VERSION ""

NS_ :

BS_:

BU_:
	NEO
	MCU
	GTW
	EPAS
	DI
	ESP
	SBW
	STW
	APP
	DAS
	XXX

VAL_TABLE_ StW_AnglHP_Spd 16383 "SNA" ;
VAL_TABLE_ DI_aebFaultReason 15 "DI_AEB_FAULT_DAS_REQ_DI_UNAVAIL" 14 "DI_AEB_FAULT_ACCEL_REQ_INVALID" 13 "DI_AEB_FAULT_MIN_TIME_BTWN_EVENTS" 12 "DI_AEB_FAULT_ESP_MIA" 11 "DI_AEB_FAULT_ESP_FAULT" 10 "DI_AEB_FAULT_EPB_NOT_PARKED" 9 "DI_AEB_FAULT_ACCEL_OUT_OF_BOUNDS" 8 "DI_AEB_FAULT_PM_REQUEST" 7 "DI_AEB_FAULT_VEL_EST_ABNORMAL" 6 "DI_AEB_FAULT_DAS_SNA" 5 "DI_AEB_FAULT_DAS_CONTROL_MIA" 4 "DI_AEB_FAULT_SPEED_DELTA" 3 "DI_AEB_FAULT_EBR_FAULT" 2 "DI_AEB_FAULT_PM_MIA" 1 "DI_AEB_FAULT_EPB_MIA" 0 "DI_AEB_FAULT_NONE" ;
VAL_TABLE_ DI_aebLockState 3 "AEB_LOCK_STATE_SNA" 2 "AEB_LOCK_STATE_UNUSED" 1 "AEB_LOCK_STATE_UNLOCKED" 0 "AEB_LOCK_STATE_LOCKED" ;
VAL_TABLE_ DI_aebSmState 7 "DI_AEB_STATE_FAULT" 6 "DI_AEB_STATE_EXIT" 5 "DI_AEB_STATE_STANDSTILL" 4 "DI_AEB_STATE_STOPPING" 3 "DI_AEB_STATE_ENABLE" 2 "DI_AEB_STATE_ENABLE_INIT" 1 "DI_AEB_STATE_STANDBY" 0 "DI_AEB_STATE_UNAVAILABLE" ;
VAL_TABLE_ DI_aebState 7 "AEB_CAN_STATE_SNA" 4 "AEB_CAN_STATE_FAULT" 3 "AEB_CAN_STATE_STANDSTILL" 2 "AEB_CAN_STATE_ENABLED" 1 "AEB_CAN_STATE_STANDBY" 0 "AEB_CAN_STATE_UNAVAILABLE" ;
VAL_TABLE_ DI_epbInterfaceReady 1 "EPB_INTERFACE_READY" 0 "EPB_INTERFACE_NOT_READY" ;
VAL_TABLE_ DI_gear 7 "DI_GEAR_SNA" 4 "DI_GEAR_D" 3 "DI_GEAR_N" 2 "DI_GEAR_R" 1 "DI_GEAR_P" 0 "DI_GEAR_INVALID" ;
VAL_TABLE_ DI_gpoReason 8 "DI_GPO_NUMREASONS" 7 "DI_GPO_CAPACITOR_OVERTEMP" 6 "DI_GPO_NOT_ENOUGH_12V" 5 "DI_GPO_NO_BATTERY_POWER" 4 "DI_GPO_AMBIENT_OVERTEMP" 3 "DI_GPO_FLUID_DELTAT" 2 "DI_GPO_STATOR_OVERTEMP" 1 "DI_GPO_HEATSINK_OVERTEMP" 0 "DI_GPO_OUTLET_OVERTEMP" ;
VAL_TABLE_ DI_immobilizerCondition 1 "DI_IMM_CONDITION_LEARNED" 0 "DI_IMM_CONDITION_VIRGIN_SNA" ;
VAL_TABLE_ DI_immobilizerState 7 "DI_IMM_STATE_FAULT" 6 "DI_IMM_STATE_FAULTRETRY" 5 "DI_IMM_STATE_RESET" 4 "DI_IMM_STATE_LEARN" 3 "DI_IMM_STATE_DISARMED" 2 "DI_IMM_STATE_AUTHENTICATING" 1 "DI_IMM_STATE_REQUEST" 0 "DI_IMM_STATE_INIT_SNA" ;
VAL_TABLE_ DI_limpReason 24 "DI_LIMP_NUMREASONS" 23 "DI_LIMP_CAPACITOR_OVERTEMP" 22 "DI_LIMP_GTW_MIA" 21 "DI_LIMP_TRQCMD_VALIDITY_UNKNOWN" 20 "DI_LIMP_DI_MIA" 19 "DI_LIMP_CONFIG_MISMATCH" 18 "DI_LIMP_HEATSINK_TEMP" 17 "DI_LIMP_PMREQUEST" 16 "DI_LIMP_PMHEARTBEAT" 15 "DI_LIMP_TRQ_CROSS_CHECK" 14 "DI_LIMP_EXTERNAL_COMMAND" 13 "DI_LIMP_WRONG_CS_CALIBRATION" 12 "DI_LIMP_STATOR_TEMP" 11 "DI_LIMP_DELTAT_TOO_NEGATIVE" 10 "DI_LIMP_DELTAT_TOO_POSITIVE" 9 "DI_LIMP_AMBIENT_TEMP" 8 "DI_LIMP_OUTLET_TEMP" 7 "DI_LIMP_LOW_FLOW" 6 "DI_LIMP_BMS_MIA" 5 "DI_LIMP_12V_SUPPLY_UNDERVOLTAGE" 4 "DI_LIMP_NO_FLUID" 3 "DI_LIMP_NO_FUNC_HEATSINK_SENSOR" 2 "DI_LIMP_NO_FUNC_STATORT_SENSOR" 1 "DI_LIMP_BUSV_SENSOR_IRRATIONAL" 0 "DI_LIMP_PHASE_IMBALANCE" ;
VAL_TABLE_ DI_mode 2 "DI_MODE_DYNO" 1 "DI_MODE_DRIVE" 0 "DI_MODE_UNDEF" ;
VAL_TABLE_ DI_motorType 14 "DI_MOTOR_F2AE" 13 "DI_MOTOR_F2AD" 12 "DI_MOTOR_F2AC" 11 "DI_MOTOR_F2AB" 10 "DI_MOTOR_F1AC" 9 "DI_MOTOR_SSR1A" 8 "DI_MOTOR_F1A" 7 "DI_MOTOR_M7M6" 6 "DI_MOTOR_M8A" 5 "DI_MOTOR_M7M5" 4 "DI_MOTOR_M7M4" 3 "DI_MOTOR_M7M3" 2 "DI_MOTOR_ROADSTER_SPORT" 1 "DI_MOTOR_ROADSTER_BASE" 0 "DI_MOTOR_SNA" ;
VAL_TABLE_ DI_speedUnits 1 "DI_SPEED_KPH" 0 "DI_SPEED_MPH" ;
VAL_TABLE_ DI_state 4 "DI_STATE_ENABLE" 3 "DI_STATE_FAULT" 2 "DI_STATE_CLEAR_FAULT" 1 "DI_STATE_STANDBY" 0 "DI_STATE_PREAUTH" ;
VAL_TABLE_ DI_velocityEstimatorState 4 "VE_STATE_BACKUP_MOTOR" 3 "VE_STATE_BACKUP_WHEELS_B" 2 "VE_STATE_BACKUP_WHEELS_A" 1 "VE_STATE_WHEELS_NORMAL" 0 "VE_STATE_NOT_INITIALIZED" ;

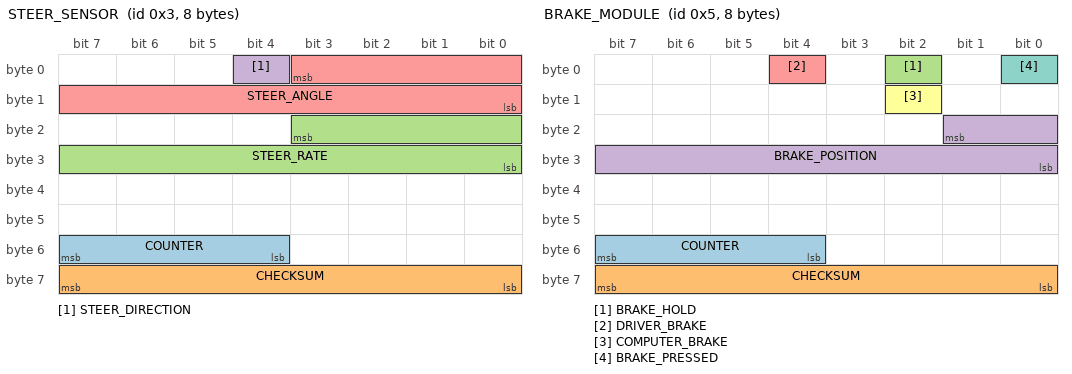
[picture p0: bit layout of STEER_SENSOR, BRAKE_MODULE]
BO_ 3 STEER_SENSOR: 8 XXX
 SG_ COUNTER : 55|4@0+ (1,0) [0|15] "" XXX
 SG_ CHECKSUM : 63|8@0+ (1,0) [0|255] "" XXX
 SG_ STEER_RATE : 19|12@0- (0.5,0) [0|255] "" XXX
 SG_ STEER_DIRECTION : 4|1@0+ (1,2) [0|1] "" XXX
 SG_ STEER_ANGLE : 3|12@0- (-0.5,0) [-500|500] "degrees" XXX

BO_ 5 BRAKE_MODULE: 8 XXX
 SG_ COUNTER : 55|4@0+ (1,0) [0|15] "" XXX
 SG_ CHECKSUM : 63|8@0+ (1,0) [0|255] "" XXX
 SG_ BRAKE_HOLD : 2|1@0+ (1,0) [0|1] "" XXX
 SG_ BRAKE_POSITION : 17|10@0+ (1,0) [0|65535] "" XXX
 SG_ DRIVER_BRAKE : 4|1@0+ (1,0) [0|1] "" XXX
 SG_ COMPUTER_BRAKE : 10|1@0+ (1,0) [0|1] "" XXX
 SG_ BRAKE_PRESSED : 0|1@1+ (1,0) [0|1] "" XXX

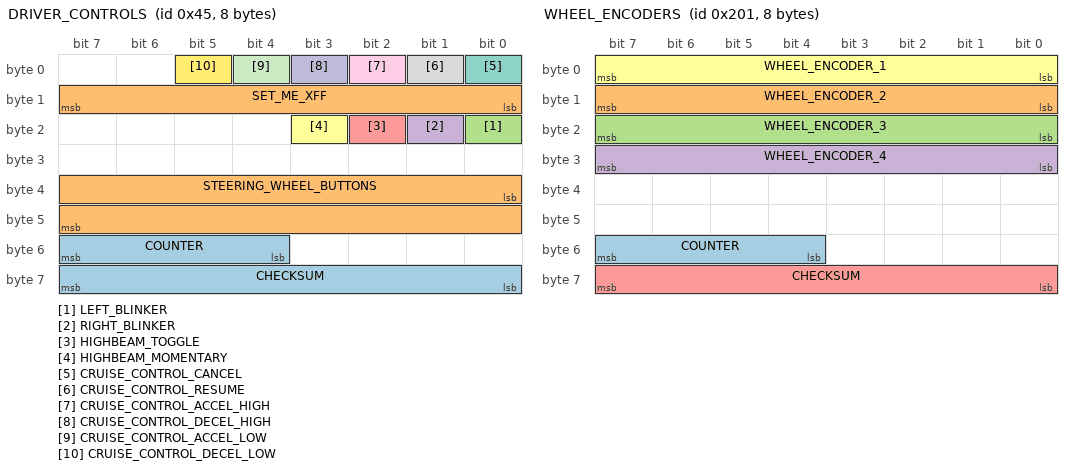
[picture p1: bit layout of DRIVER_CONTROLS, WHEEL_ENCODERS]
BO_ 69 DRIVER_CONTROLS: 8 XXX
 SG_ COUNTER : 55|4@0+ (1,0) [0|15] "" XXX
 SG_ STEERING_WHEEL_BUTTONS : 32|16@1+ (1,0) [0|255] "4 directional, 2 volume control & 2 phone buttons" XXX
 SG_ LEFT_BLINKER : 16|1@0+ (1,0) [0|1] "" XXX
 SG_ RIGHT_BLINKER : 17|1@0+ (1,0) [0|1] "" XXX
 SG_ HIGHBEAM_TOGGLE : 18|1@0+ (1,0) [0|1] "" XXX
 SG_ HIGHBEAM_MOMENTARY : 19|1@0+ (1,0) [0|1] "" XXX
 SG_ CRUISE_CONTROL_CANCEL : 0|1@0+ (1,0) [0|1] "" XXX
 SG_ CRUISE_CONTROL_RESUME : 1|1@0+ (1,0) [0|1] "" XXX
 SG_ CRUISE_CONTROL_ACCEL_HIGH : 2|1@0+ (1,0) [0|1] "" XXX
 SG_ CRUISE_CONTROL_DECEL_HIGH : 3|1@0+ (1,0) [0|1] "" XXX
 SG_ CRUISE_CONTROL_ACCEL_LOW : 4|1@0+ (1,0) [0|1] "" XXX
 SG_ CRUISE_CONTROL_DECEL_LOW : 5|1@0+ (1,0) [0|1] "" XXX
 SG_ CHECKSUM : 63|8@0+ (1,0) [0|255] "" XXX
 SG_ SET_ME_XFF : 15|8@0+ (1,0) [0|255] "" XXX

BO_ 513 WHEEL_ENCODERS: 8 XXX
 SG_ COUNTER : 55|4@0+ (1,0) [0|15] "" XXX
 SG_ WHEEL_ENCODER_2 : 15|8@0+ (1,0) [0|255] "" XXX
 SG_ WHEEL_ENCODER_3 : 23|8@0+ (1,0) [0|255] "" XXX
 SG_ WHEEL_ENCODER_4 : 31|8@0+ (1,0) [0|255] "" XXX
 SG_ CHECKSUM : 56|8@1+ (1,0) [0|255] "" XXX
 SG_ WHEEL_ENCODER_1 : 7|8@0+ (1,0) [0|255] "" XXX

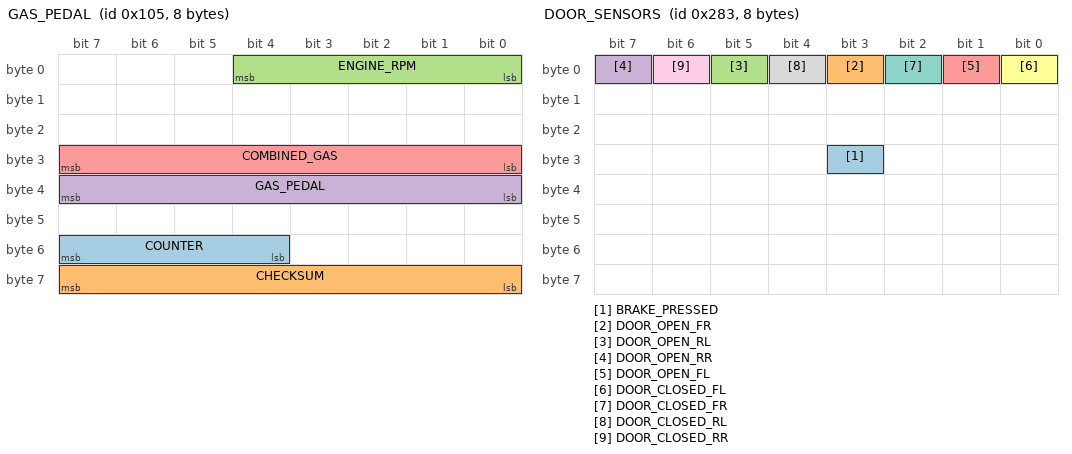
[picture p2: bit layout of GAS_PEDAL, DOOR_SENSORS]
BO_ 261 GAS_PEDAL: 8 XXX
 SG_ COUNTER : 55|4@0+ (1,0) [0|15] "" XXX
 SG_ CHECKSUM : 63|8@0+ (1,0) [0|255] "" XXX
 SG_ ENGINE_RPM : 4|5@0+ (1,0) [0|255] "" XXX
 SG_ GAS_PEDAL : 39|8@0+ (1,0) [0|255] "" XXX
 SG_ COMBINED_GAS : 31|8@0+ (1,0) [0|255] "" XXX

BO_ 643 DOOR_SENSORS: 8 XXX
 SG_ BRAKE_PRESSED : 27|1@0+ (1,0) [0|1] "" XXX
 SG_ DOOR_OPEN_FR : 3|1@1+ (1,0) [0|3] "" XXX
 SG_ DOOR_OPEN_RL : 5|1@0+ (1,0) [0|3] "" XXX
 SG_ DOOR_OPEN_RR : 7|1@0+ (1,0) [0|3] "" XXX
 SG_ DOOR_OPEN_FL : 1|1@0+ (1,0) [0|1] "" XXX
 SG_ DOOR_CLOSED_FL : 0|1@0+ (1,0) [0|1] "" XXX
 SG_ DOOR_CLOSED_FR : 2|1@0+ (1,0) [0|1] "" XXX
 SG_ DOOR_CLOSED_RL : 4|1@0+ (1,0) [0|1] "" XXX
 SG_ DOOR_CLOSED_RR : 6|1@0+ (1,0) [0|1] "" XXX

BO_ 885 SEATBELT_SENSORS: 8 XXX
 SG_ SEATBELT_DRIVER_LATCHED : 16|1@0+ (1,0) [0|1] "" XXX
 SG_ SEATBELT_PASSENGER_LATCHED : 18|1@0+ (1,0) [0|1] "" XXX

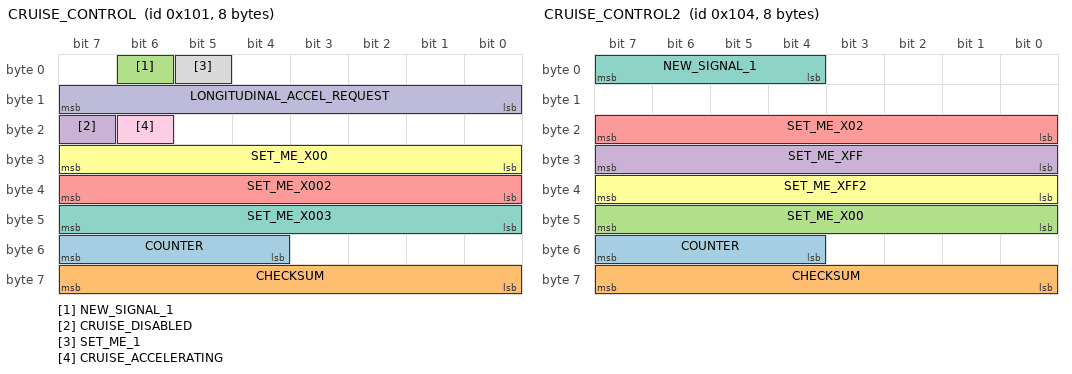
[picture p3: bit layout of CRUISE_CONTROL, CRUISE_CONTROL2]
BO_ 257 CRUISE_CONTROL: 8 XXX
 SG_ COUNTER : 55|4@0+ (1,0) [0|15] "" XXX
 SG_ CHECKSUM : 63|8@0+ (1,0) [0|255] "" XXX
 SG_ NEW_SIGNAL_1 : 6|1@0+ (1,0) [0|255] "" XXX
 SG_ CRUISE_DISABLED : 23|1@0+ (1,0) [0|1] "" XXX
 SG_ SET_ME_X002 : 39|8@0+ (1,0) [0|255] "" XXX
 SG_ SET_ME_X00 : 31|8@0+ (1,0) [0|255] "" XXX
 SG_ SET_ME_X003 : 47|8@0+ (1,0) [0|255] "" XXX
 SG_ SET_ME_1 : 5|1@0+ (1,0) [0|1] "" XXX
 SG_ CRUISE_ACCELERATING : 22|1@0+ (1,0) [0|1] "" XXX
 SG_ LONGITUDINAL_ACCEL_REQUEST : 15|8@0- (1,0) [0|127] "" XXX

BO_ 260 CRUISE_CONTROL2: 8 XXX
 SG_ COUNTER : 55|4@0+ (1,0) [0|15] "" XXX
 SG_ CHECKSUM : 63|8@0+ (1,0) [0|255] "" XXX
 SG_ SET_ME_X00 : 47|8@0+ (1,0) [0|255] "" XXX
 SG_ SET_ME_XFF : 31|8@0+ (1,0) [0|65535] "" XXX
 SG_ SET_ME_X02 : 23|8@0+ (1,0) [0|255] "" XXX
 SG_ SET_ME_XFF2 : 39|8@0+ (1,0) [0|255] "" XXX
 SG_ NEW_SIGNAL_1 : 7|4@0+ (1,0) [0|255] "" XXX

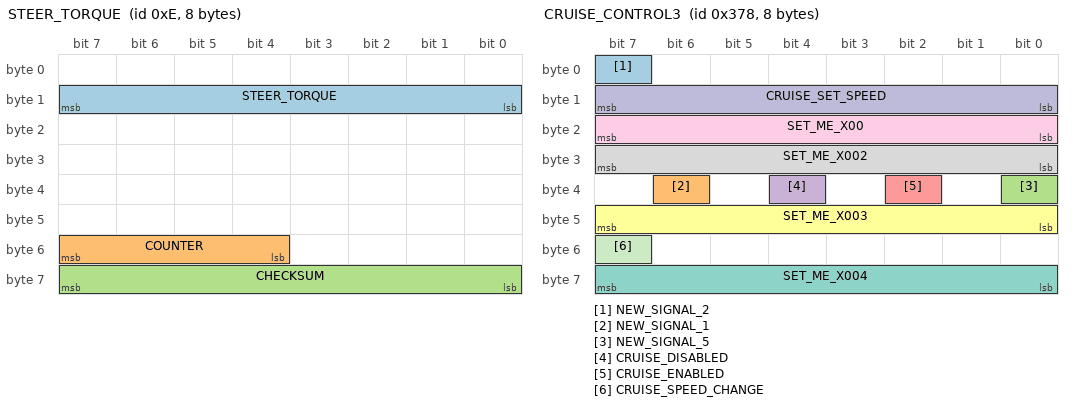
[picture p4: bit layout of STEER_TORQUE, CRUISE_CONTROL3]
BO_ 14 STEER_TORQUE: 8 XXX
 SG_ STEER_TORQUE : 15|8@0+ (1,0) [0|255] "" XXX
 SG_ COUNTER : 55|4@0+ (1,0) [0|15] "" XXX
 SG_ CHECKSUM : 63|8@0+ (1,0) [0|255] "" XXX

BO_ 888 CRUISE_CONTROL3: 8 XXX
 SG_ NEW_SIGNAL_2 : 7|1@0+ (1,0) [0|1] "" XXX
 SG_ NEW_SIGNAL_1 : 38|1@0+ (1,0) [0|1] "" XXX
 SG_ NEW_SIGNAL_5 : 32|1@0+ (1,0) [0|1] "" XXX
 SG_ CRUISE_DISABLED : 36|1@0+ (1,0) [0|1] "" XXX
 SG_ CRUISE_ENABLED : 34|1@0+ (1,0) [0|1] "" XXX
 SG_ SET_ME_X003 : 47|8@0+ (1,0) [0|255] "" XXX
 SG_ SET_ME_X004 : 63|8@0+ (1,0) [0|255] "" XXX
 SG_ SET_ME_X002 : 31|8@0+ (1,0) [0|255] "" XXX
 SG_ SET_ME_X00 : 23|8@0+ (1,0) [0|255] "" XXX
 SG_ CRUISE_SET_SPEED : 15|8@0+ (1,0) [0|63] "mph" XXX
 SG_ CRUISE_SPEED_CHANGE : 55|1@0+ (1,0) [0|1] "" XXX

BO_ 307 POWER_SEATS: 8 XXX
 SG_ DRIVER_FORWARD : 0|1@0+ (1,0) [0|1] "" XXX
 SG_ DRIVER_BACK : 1|1@0+ (1,0) [0|1] "" XXX

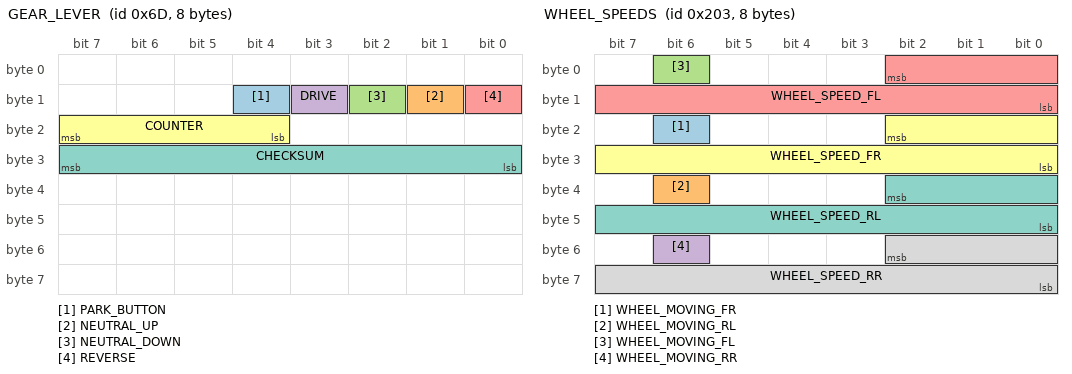
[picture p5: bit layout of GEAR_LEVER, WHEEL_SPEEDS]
BO_ 109 GEAR_LEVER: 8 XXX
 SG_ PARK_BUTTON : 12|1@0+ (1,0) [0|1] "" XXX
 SG_ NEUTRAL_UP : 9|1@0+ (1,0) [0|1] "" XXX
 SG_ NEUTRAL_DOWN : 10|1@0+ (1,0) [0|1] "" XXX
 SG_ DRIVE : 11|1@0+ (1,0) [0|1] "" XXX
 SG_ REVERSE : 8|1@0+ (1,0) [0|1] "" XXX
 SG_ COUNTER : 23|4@0+ (1,0) [0|15] "" XXX
 SG_ CHECKSUM : 31|8@0+ (1,0) [0|255] "" XXX

BO_ 115 GEAR_PACKET: 8 XXX
 SG_ GEAR : 0|4@1+ (1,0) [0|15] "" XXX

BO_ 581 IGNITION: 8 XXX

BO_ 515 WHEEL_SPEEDS: 8 XXX
 SG_ WHEEL_MOVING_FR : 22|1@1+ (1,0) [0|15] "" XXX
 SG_ WHEEL_MOVING_RL : 38|1@0+ (1,0) [0|1] "" XXX
 SG_ WHEEL_MOVING_FL : 6|1@0+ (1,0) [0|1] "" XXX
 SG_ WHEEL_MOVING_RR : 54|1@0+ (1,0) [0|1] "" XXX
 SG_ WHEEL_SPEED_FL : 2|11@0+ (0.0375,0) [0|255] "mph" XXX
 SG_ WHEEL_SPEED_FR : 18|11@0+ (0.0375,0) [0|255] "mph" XXX
 SG_ WHEEL_SPEED_RL : 34|11@0+ (0.0375,0) [0|255] "mph" XXX
 SG_ WHEEL_SPEED_RR : 50|11@0+ (0.0375,0) [0|255] "mph" XXX

BU_: PowertrainControlModule InstrumentCluster ElectricPowerSteering AntilockBrakeSystem

CM_ "AUTOGENERATED FILE, DO NOT EDIT";

CM_ "Imported file _honda_common.dbc starts here";
CM_ SG_ 304 "Seems to be platform-agnostic";
CM_ SG_ 316 "Should exist on Nidec";
CM_ SG_ 420 BRAKE_HOLD_RELATED "On when Brake Hold engaged";
CM_ SG_ 490 LONG_ACCEL "wheel speed derivative, noisy and zero snapping";
CM_ SG_ 773 PASS_AIRBAG_ON "Might just be indicator light";
CM_ SG_ 773 PASS_AIRBAG_OFF "Might just be indicator light";
CM_ SG_ 780 CRUISE_SPEED "255 = no speed";
CM_ SG_ 780 PCM_SPEED "Used by Nidec";
CM_ SG_ 780 PCM_GAS "Used by Nidec";
CM_ SG_ 804 CRUISE_SPEED_PCM "255 = no speed";

CM_ "Imported file _bosch_2018.dbc starts here";
CM_ SG_ 450 EPB_STATE "3: On, 2: Disengaging, 1: Engaging, 0: Off";
CM_ SG_ 576 LINE_DISTANCE_VISIBLE "Length of line visible, undecoded";
CM_ SG_ 577 LINE_FAR_EDGE_POSITION "Appears to be a measure of line thickness, indicates location of the portion of the line furthest from the car, undecoded";
CM_ SG_ 577 LINE_PARAMETER "Unclear if this is low quality line curvature rate or if this is something else, but it is correlated with line curvature, undecoded";
CM_ SG_ 577 LINE_DASHED "1 = line is dashed";
CM_ SG_ 577 LINE_SOLID "1 = line is solid";

CM_ "Imported file _bosch_adas_2018.dbc starts here";
CM_ SG_ 479 CONTROL_ON "Set to 5 when car is being controlled";
CM_ SG_ 479 AEB_STATUS "set for the duration of AEB event";
CM_ SG_ 479 AEB_BRAKING "set when braking is commanded during AEB event";
CM_ SG_ 479 AEB_PREPARE "set 1s before AEB";
CM_ SG_ 829 BEEP "beeps are pleasant, chimes are for warnngs etc...";

CM_ "Imported file _steering_sensors_a.dbc starts here";
CM_ "honda_accord_2018_can.dbc starts here";

VAL_ 357 Cruise_State 4 "active" 3 "standby" 0 "off" ;
VAL_ 970 Lkas_Action 15 "off" 9 "abrupt" 8 "abrupt2" 5 "smooth" 4 "smooth2" ;
VAL_ 970 Lkas_Alert 15 "no_alert" 3 "high_intensity" 2 "mid_intensity" 1 "low_intensity" ;
VAL_ 972 LaActAvail_D_Actl 3 "available" 2 "tbd" 1 "not_available" 0 "fault" ;
